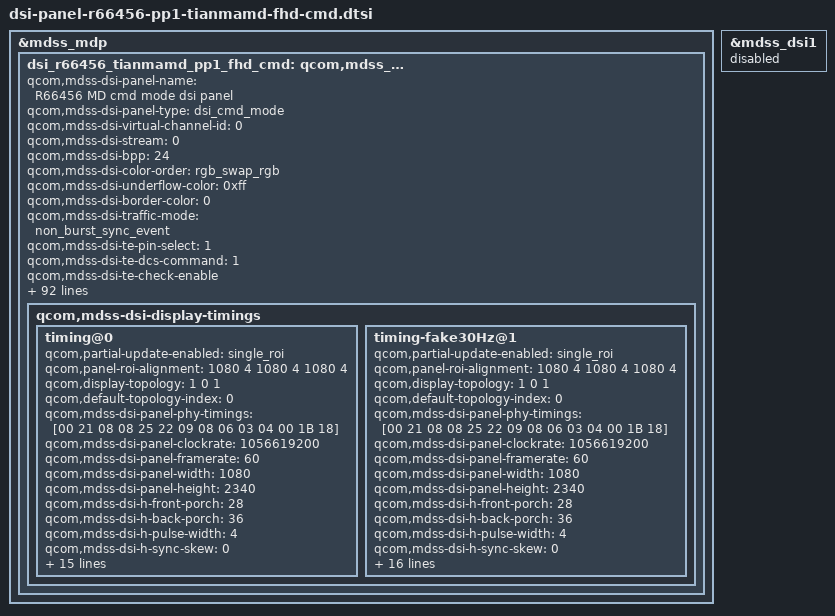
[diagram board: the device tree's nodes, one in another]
/* Copyright (c) 2014, Code Aurora Forum. All rights reserved.
 *
 * This program is free software; you can redistribute it and/or modify
 * it under the terms of the GNU General Public License version 2 and
 * only version 2 as published by the Free Software Foundation.
 *
 * This program is distributed in the hope that it will be useful,
 * but WITHOUT ANY WARRANTY; without even the implied warranty of
 * MERCHANTABILITY or FITNESS FOR A PARTICULAR PURPOSE.  See the
 * GNU General Public License for more details.
 */

&mdss_mdp {
    dsi_r66456_tianmamd_pp1_fhd_cmd: qcom,mdss_dsi_r66456_tianmamd_pp1_fhd_cmd {
		qcom,mdss-dsi-panel-name = "R66456 MD cmd mode dsi panel";
		qcom,mdss-dsi-panel-type = "dsi_cmd_mode";
		qcom,mdss-dsi-virtual-channel-id = <0>;
		qcom,mdss-dsi-stream = <0>;
		qcom,mdss-dsi-bpp = <24>;
		qcom,mdss-dsi-color-order = "rgb_swap_rgb";
		qcom,mdss-dsi-underflow-color = <0xff>;
		qcom,mdss-dsi-border-color = <0>;
		qcom,mdss-dsi-traffic-mode = "non_burst_sync_event";
		qcom,mdss-dsi-te-pin-select = <1>;
		qcom,mdss-dsi-te-dcs-command = <1>;
		qcom,mdss-dsi-te-check-enable;
		qcom,mdss-dsi-te-using-te-pin;
		qcom,mdss-dsi-lane-map = "lane_map_0123";
		qcom,mdss-dsi-bllp-eof-power-mode;
		qcom,mdss-dsi-bllp-power-mode;
		qcom,mdss-dsi-lane-0-state;
		qcom,mdss-dsi-lane-1-state;
		qcom,mdss-dsi-lane-2-state;
		qcom,mdss-dsi-lane-3-state;
		qcom,mdss-dsi-reset-sequence = <1 10>, <0 2>, <1 10>;
		qcom,mdss-dsi-dma-trigger = "trigger_sw";
		qcom,mdss-dsi-mdp-trigger = "none";
		qcom,mdss-dsi-wr-mem-start = <0x2c>;
		qcom,mdss-dsi-wr-mem-continue = <0x3c>;
		qcom,mdss-dsi-lp11-init;
		qcom,mdss-dsi-tx-eot-append;
		qcom,ulps-enabled;
		qcom,mdss-dsi-panel-hdr-enabled;
		qcom,mdss-dsi-panel-hdr-color-primaries = <14880 15935 32435 16555 14945 30910 7790 3415>;
		qcom,mdss-dsi-panel-peak-brightness = <5643000>;
		qcom,mdss-dsi-panel-blackness-level = <6134>;
		qcom,esd-check-enabled;
		qcom,mdss-dsi-panel-status-check-mode = "te_signal_check";

		lge,blmap = <
			0
			8 8 8 8 8 8 8 8 8 8 9 11 12 13 15 16 17 18 20 21
			22 24 25 26 28 29 30 32 33 34 35 37 38 39 41 42 43 45 46 47
			49 50 52 53 54 56 57 58 60 61 62 64 65 66 68 69 71 72 73 75
			76 81 86 91 96 100 105 110 115 120 125 130 135 139 144 149 154 159 164 169
			174 179 184 189 193 198 203 208 213 218 224 229 234 239 244 249 254 259 264 269
			274 279 285 290 295 300 305 310 319 328 337 346 355 364 373 382 392 401 410 419
			428 437 446 455 464 473 482 491 500 509 518 527 536 546 555 564 574 583 593 602
			611 620 630 639 649 658 668 677 686 696 705 715 724 734 743 752 762 771 781 797
			813 829 845 861 877 893 910 926 942 958 974 990 1006 1022 1038 1054 1070 1086 1102 1118
			1134 1150 1167 1183 1199 1215 1231 1247 1263 1279 1295 1311 1327 1343 1359 1375 1391 1407 1424 1440
			1456 1472 1488 1504 1520 1536 1552 1574 1597 1619 1641 1664 1686 1708 1731 1753 1775 1798 1820 1842
			1864 1887 1909 1931 1954 1976 1998 2021 2043 2065 2088 2110 2134 2159 2183 2207 2231 2256 2280 2304
			2328 2353 2377 2401 2425 2450 2474 2498 2522 2547 2571 2595 2619 2644 2668 2669 2670 2671 2672 2673
			2674 2675 2676 2677 2678 2679 2680 2681 2682 2683 2685 2686 2687 2688 2689 2690 2691 2692 2693 2694
			2695 2696 2697 2698 2699 2700 2713 2725 2738 2750 2763 2775 2788 2800 2813 2825 2838 2850 2863 2875
			2888 2900 2906 2911 2917 2922 2928 2933 2939 2944 2950 2956 2961 2967 2972 2978 2983 2989 2994 3000
			3012 3023 3035 3046 3058 3069 3081 3092 3104 3115 3127 3138 3150 3162 3173 3185 3196 3208 3219 3231
			3242 3254 3265 3277 3288 3300 3311 3321 3332 3343 3353 3364 3375 3385 3396 3407 3418 3428 3439 3450
			3460 3471 3482 3492 3503
		>;
		lge,blmap-ve = <
			0
			8 8 8 8 8 8 8 8 8 8 10 12 13 15 17 19 21 23 24 26
			28 30 32 33 35 37 39 41 42 44 46 48 50 52 53 55 57 59 61 62
			64 66 68 69 71 73 75 77 78 80 82 84 86 87 89 91 93 94 96 98
			100 106 113 119 125 132 138 145 151 157 164 170 177 183 189 196 202 209 215 221
			228 234 241 248 253 260 267 273 280 287 293 300 307 314 320 327 334 340 347 354
			360 367 374 380 387 394 400 407 419 431 443 455 466 478 490 502 514 526 538 550
			562 574 585 597 609 621 633 645 657 669 681 692 704 716 729 741 753 766 778 790
			803 815 827 839 852 864 877 889 901 914 926 938 951 963 975 988 1000 1013 1025 1047
			1068 1089 1110 1131 1152 1173 1194 1215 1236 1257 1279 1300 1321 1342 1363 1384 1405 1426 1447 1468
			1489 1510 1532 1553 1574 1595 1616 1637 1658 1679 1700 1721 1742 1764 1785 1806 1827 1848 1869 1890
			1911 1932 1953 1974 1996 2017 2038 2067 2096 2126 2155 2184 2214 2243 2272 2301 2331 2360 2389 2419
			2448 2477 2507 2536 2565 2595 2624 2653 2682 2712 2741 2770 2802 2834 2866 2898 2930 2962 2994 3026
			3058 3090 3122 3154 3186 3218 3249 3281 3313 3345 3377 3409 3441 3473 3505 3505 3505 3505 3505 3505
			3505 3505 3505 3505 3505 3505 3505 3505 3505 3505 3505 3505 3505 3505 3505 3505 3505 3505 3505 3505
			3505 3505 3505 3505 3505 3505 3505 3505 3505 3505 3505 3505 3505 3505 3505 3505 3505 3505 3505 3505
			3505 3505 3505 3505 3505 3505 3505 3505 3505 3505 3505 3505 3505 3505 3505 3505 3505 3505 3505 3505
			3505 3505 3505 3505 3505 3505 3505 3505 3505 3505 3505 3505 3505 3505 3505 3505 3505 3505 3505 3505
			3505 3505 3505 3505 3505 3505 3505 3505 3505 3505 3505 3505 3505 3505 3505 3505 3505 3505 3505 3505
			3505 3505 3505 3505 3505
		>;
		lge,blmap-ex = <
			0
			7 7 7 7 7 7 7 7 7 8 10 11 12 14 15 16 18 19 20 22
			23 24 26 27 28 30 31 32 34 35 36 38 39 40 42 43 47 52 56 60
			65 69 74 78 82 87 91 95 100 104 108 113 117 121 126 130 135 139 143 148
			152 156 161 165 169 174 178 182 187 191 196 200 204 209 213 220 227 234 240 247
			254 261 268 275 282 289 295 302 309 316 323 330 337 343 350 357 364 369 374 380
			385 390 395 400 405 411 416 421 426 431 436 442 447 452 457 462 466 471 475 480
			484 489 494 498 503 507 512 517 521 526 530 535 539 544 544 544 544 544 544 544
			552 561 569 578 586 595 603 611 620 628 637 645 653 662 670 679 687 696 704
		>;
		lge,blmap-hdr = <
			0
			8 8 8 8 8 8 8 8 8 8 10 11 13 15 16 18 20 21 23 24
			26 28 29 31 33 34 36 38 39 41 43 44 46 48 49 51 53 54 56 57
			59 61 62 64 66 67 69 71 72 74 76 77 79 81 82 84 85 87 89 90
			92 98 104 110 116 122 127 133 139 145 151 157 163 169 175 181 187 192 198 204
			210 216 223 229 234 240 246 252 258 265 271 277 283 289 295 302 308 314 320 326
			332 339 345 351 357 363 369 376 387 397 408 419 430 441 452 463 474 485 496 507
			518 529 540 551 562 573 584 595 606 617 628 639 650 661 672 684 695 706 718 729
			741 752 763 774 786 797 809 820 832 843 854 866 877 889 900 911 923 934 946 966
			985 1004 1024 1043 1063 1082 1102 1121 1141 1160 1180 1199 1219 1238 1257 1277 1296 1316 1335 1355
			1374 1394 1413 1433 1452 1471 1491 1510 1530 1549 1569 1588 1608 1627 1647 1666 1686 1705 1724 1744
			1763 1783 1802 1822 1841 1861 1880 1907 1934 1961 1988 2015 2042 2069 2096 2123 2150 2178 2205 2232
			2259 2286 2313 2340 2367 2394 2421 2448 2475 2502 2529 2556 2585 2615 2644 2674 2703 2732 2762 2791
			2821 2850 2879 2909 2938 2967 2997 3026 3056 3085 3114 3144 3173 3203 3232 3233 3233 3234 3234 3235
			3235 3236 3237 3237 3238 3238 3239 3240 3240 3241 3241 3242 3242 3243 3244 3244 3245 3245 3246 3247
			3247 3248 3248 3249 3249 3250 3255 3260 3265 3270 3275 3280 3285 3290 3296 3303 3309 3315 3321 3328
			3334 3340 3343 3346 3348 3351 3354 3357 3359 3362 3365 3368 3371 3373 3376 3379 3382 3384 3387 3390
			3393 3396 3399 3402 3405 3408 3412 3415 3418 3421 3424 3427 3430 3432 3435 3437 3439 3442 3444 3446
			3448 3451 3453 3455 3458 3460 3462 3465 3467 3469 3471 3474 3476 3478 3480 3483 3485 3487 3489 3492
			3494 3496 3498 3501 3503
		>;
		qcom,mdss-pan-physical-width-dimension = <68>;
		qcom,mdss-pan-physical-height-dimension = <147>;

		qcom,mdss-dsi-t-clk-post = <0x18>;
		qcom,mdss-dsi-t-clk-pre = <0x1B>;

		lge,use-ambient;
		lge,aod-interface-data = "semi-partial", "semi-partial", "semi-partial";
		lge,mdss-dsi-nolp-command = [
			15 01 00 00 00 00 02 B0 03
			39 01 00 00 5A 00 03 51 00 00
			15 01 00 00 32 00 02 88 00
		];
		lge,mdss-dsi-nolp-command-state = "dsi_lp_mode";

//		lge,mdss-dsi-aod-area-command = [
//			15 01 00 00 00 00 02 FE 00
//			39 01 00 00 00 00 05 30 00 00 04 37
//		];
//		lge,mdss-dsi-aod-area-command-state = "dsi_lp_mode";

		lge,mdss-dsi-lp2-command = [
			15 01 00 00 00 00 02 B0 03
			39 01 00 00 5A 00 03 51 00 00
			15 01 00 00 32 00 02 88 01
		];
		lge,mdss-dsi-lp2-command-state = "dsi_lp_mode";

		lge,use-color-manager;
		lge,color-mode-cmds-dummy = [
			15 01 00 00 00 00 02 B0 00
			39 01 00 00 00 00 43 CE C1 1C F8 FF F4 EF 0A 0A 14 EF D3 EF DC E0 2B FE EB 03 00 FB F5 F5 E5 FF B6 97 E6 B6 97 3C 00 00 00 00 00 00 00 00 00 00 00 00 00 00 00 00 00 00 00 00 00 00 00 00 00 00 00 00 00 00 00 00 00 00 00 08
			15 01 00 00 00 00 02 B0 03
		];
		lge,color-mode-cmds-dummy-state = "dsi_hs_mode";
		lge,color-mode-set = [
			39 01 00 00 00 00 43 CE C1 1C F8 FF F4 EF 0A 0A 14 EF D3 EF DC E0 2B FE EB 03 00 FB F5 F5 E5 FF B6 97 E6 B6 97 3C 00 00 00 00 00 00 00 00 00 00 00 00 00 00 00 00 00 00 00 00 00 00 00 00 00 00 00 00 00 00 00 00 00 00 00 08
			39 01 00 00 00 00 43 CE C1 1C FC EF BC 0A 0D 31 D9 0B 29 D9 EC E6 D8 F1 F1 E4 E9 EE EA FD 13 FF 00 00 FC 19 00 FF 00 FF 00 67 F8 00 FF 00 00 FF 41 26 E6 FF 00 FF FF 74 F9 EC FF FF 00 FF FB 2D F6 FF FF FF 00 FD FC 00 FF 08
			39 01 00 00 00 00 43 CE C1 1C FC EF BB 00 D9 E3 09 EB E3 DC EE E5 F2 EE E3 F7 D8 E6 09 E9 DD FF 00 00 F0 47 31 FF 00 FF 00 00 FD 37 FF 00 00 FF 3F 26 E6 FF 00 FF FF 24 FD F3 FF FF 00 FF F5 4D E1 FF FF FF 00 FD FC 46 FF 08
			39 01 00 00 00 00 43 CE C1 1C FC EF BB E2 E8 ED E1 14 E0 DC F3 E8 DC F1 E0 D9 E0 E6 DC EF D7 FF 00 00 F0 47 31 FF 00 FF 00 8F F2 4F FF 00 00 FF 3F 26 E6 FF 00 FF FF 97 F3 E8 FF FF 00 FF F0 4C F6 FF FF FF 00 FD FC 59 FF 08
			39 01 00 00 00 00 43 CE C1 1C E2 EF FF EF 0A 0A 14 EF D3 EF DC E0 2B FE EB 03 00 FB F5 F5 E5 FF B6 97 E6 B6 97 3C 00 00 00 00 00 00 00 00 00 00 00 00 00 00 00 00 00 00 00 00 00 00 00 00 00 00 00 00 00 00 00 00 00 00 00 08
			39 01 00 00 00 00 43 CE C1 1C EB F4 F4 EF 0A 0A 14 EF D3 EF DC E0 2B FE EB 03 00 FB F5 F5 E5 FF B6 97 E6 B6 97 3C 00 00 00 00 00 00 00 00 00 00 00 00 00 00 00 00 00 00 00 00 00 00 00 00 00 00 00 00 00 00 00 00 00 00 00 08
			39 01 00 00 00 00 43 CE C1 1C F8 FF F4 EF 0A 0A 14 EF D3 EF DC E0 2B FE EB 03 00 FB F5 F5 E5 FF B6 97 E6 B6 97 3C 00 00 00 00 00 00 00 00 00 00 00 00 00 00 00 00 00 00 00 00 00 00 00 00 00 00 00 00 00 00 00 00 00 00 00 08
			39 01 00 00 00 00 43 CE C0 1C F8 FF F4 EF 0A 0A 14 EF D3 EF DC E0 2B FE EB 03 00 FB F5 F5 E5 FF B6 97 E6 B6 97 3C 00 00 00 00 00 00 00 00 00 00 00 00 00 00 00 00 00 00 00 00 00 00 00 00 00 00 00 00 00 00 00 00 00 00 00 08
		];
		lge,saturation-lut = [
			39 01 00 00 00 00 2A FF 00 00 D7 28 28 FF 00 FF 00 28 D7 28 FF 00 00 FF 28 28 D7 FF 00 FF FF 28 D7 D7 FF FF 00 FF D7 28 D7 FF FF FF 00 D7 D7 28 FF
			39 01 00 00 00 00 2A FF 00 00 EB 14 14 FF 00 FF 00 14 EB 14 FF 00 00 FF 14 14 EB FF 00 FF FF 14 EB EB FF FF 00 FF EB 14 EB FF FF FF 00 EB EB 14 FF
			39 01 00 00 00 00 2A FF B6 97 E6 B6 97 3C 00 00 00 00 00 00 00 00 00 00 00 00 00 00 00 00 00 00 00 00 00 00 00 00 00 00 00 00 00 00 00 00 00 00 00
			39 01 00 00 00 00 2A FF 80 80 FF 7B 7B 5D 80 FF 80 76 FF 76 5D 80 80 FF 76 76 FF 5D 80 FF FF 76 FF FF 5D FF 80 FF FF 76 FF 5D FF FF 80 FF FF 76 5D
			39 01 00 00 00 00 2A FF 80 80 FF 76 76 5D 80 FF 80 6C FF 6C 5D 80 80 FF 6C 6C FF 5D 80 FF FF 6C FF FF 5D FF 80 FF FF 6C FF 5D FF FF 80 FF FF 6C 5D
		];
		lge,custom-rgb-hue-lut = [
			39 01 00 00 00 00 12 EF 1E 0A 14 EF F1 0F DC E0 2B EA EB 03 00 E7 E1 F5 E5
			39 01 00 00 00 00 12 EF 14 0A 14 EF E2 01 DC E0 2B F4 EB 03 00 F1 EB F5 E5
			39 01 00 00 00 00 12 EF 0A 0A 14 EF D3 EF DC E0 2B FE EB 03 00 FB F5 F5 E5
			39 01 00 00 00 00 12 EF 0A 0A 14 EF D3 EF DC E0 2B FE EB 03 00 FB F5 F5 E5
			39 01 00 00 00 00 12 EF 0A 1E 32 EF D3 EF FA E0 2B FE D7 EE 00 FB F5 E1 E5
		];
		lge,mdss-dsi-sharpness-command = [
			15 01 00 00 00 00 02 B0 00
			39 01 00 00 00 00 05 DD 33 06 07 65
			15 01 00 00 00 00 02 B0 03
		];
		lge,mdss-dsi-sharpness-command-state = "dsi_hs_mode";
		lge,sharpness-lut = [
			39 01 00 00 00 00 05 DD 33 06 07 65
			39 01 00 00 00 00 05 DD 33 06 0E 65
			39 01 00 00 00 00 05 DD 33 06 15 65
			39 01 00 00 00 00 05 DD 33 06 1C 65
			39 01 00 00 00 00 05 DD 33 06 23 65
		];
		lge,rgb-lut = [
			39 01 00 00 00 00 03 F8 FF F4
			39 01 00 00 00 00 03 F4 FB F0
			39 01 00 00 00 00 03 F0 F8 EC
			39 01 00 00 00 00 03 EC F5 E9
			39 01 00 00 00 00 03 E8 F1 E5
			39 01 00 00 00 00 03 E4 EE E2
			39 01 00 00 00 00 03 E1 EB DE
			39 01 00 00 00 00 03 DD E7 DA
			39 01 00 00 00 00 03 D9 E4 D7
			39 01 00 00 00 00 03 D5 E1 D3
			39 01 00 00 00 00 03 D1 DD D0
			39 01 00 00 00 00 03 CD DA CC
			39 01 00 00 00 00 03 CA D7 C9
			39 01 00 00 00 00 03 C6 D3 C5
			39 01 00 00 00 00 03 C2 D0 C1
			39 01 00 00 00 00 03 BE CC BE
			39 01 00 00 00 00 03 BA C9 BA
			39 01 00 00 00 00 03 B6 C6 B7
			39 01 00 00 00 00 03 B2 C2 B3
			39 01 00 00 00 00 03 AF BF AF
			39 01 00 00 00 00 03 AB BC AC
			39 01 00 00 00 00 03 A7 B8 A8
			39 01 00 00 00 00 03 A3 B5 A5
			39 01 00 00 00 00 03 9F B2 A1
		];

		/* ACO */
		lge,use-ace-ctrl;
		lge,default-ace-mode = <1>;
		lge,mdss-dsi-ace-tune-command = [
			15 01 00 00 00 00 02 B0 00
			39 01 00 00 00 00 0C BC 33 25 CD 2B 19 06 03 C0 00 00 00
			15 01 00 00 00 00 02 B0 03
			15 01 00 00 14 00 02 55 00
			15 01 00 00 14 00 02 53 00
		];
		lge,mdss-dsi-ace-cmmand-state = "dsi_hs_mode";
		lge,ace-lut = [
			39 01 00 00 00 00 0C BC 33 25 FF 2B 19 22 53 C0 00 00 00
			39 01 00 00 00 00 0C BC 3B 45 CD 2B 19 59 03 C0 00 00 00
		];

		/* IRC */
		lge,use-irc-ctrl;
		lge,mdss-dsi-irc-command = [
			15 01 00 00 00 00 02 B0 80
			15 01 00 00 00 00 02 D3 01
			15 01 00 00 00 00 02 B0 03
		];
		lge,mdss-dsi-irc-command-state = "dsi_hs_mode";

		/* FP LHBM */
		lge,use-fp-lhbm;
		lge,mdss-dsi-fp-lhbm-command = [
			15 01 00 00 00 00 02 B0 80
			15 01 00 00 14 00 02 CC 11
			15 01 00 00 00 00 02 B0 03
		];
		lge,mdss-dsi-fp-lhbm-command-state = "dsi_hs_mode";

		lge,mdss-dsi-fp-lhbm-aod-command = [
			15 01 00 00 00 00 02 B0 80
			39 01 00 00 14 00 1F B6 42 34 01 05 00 00 09 23 07 30 09 23 02 1C 01 F4 00 00 00 00 01 0E 01 0E 00 00 02 3B 58 0C
			15 01 00 00 00 00 02 B0 03
		];
		lge,mdss-dsi-fp-lhbm-aod-command-state = "dsi_hs_mode";

		lge,mdss-dsi-fp-lhbm-br-lvl-command = [
			15 01 00 00 00 00 02 B0 80
			39 01 00 00 00 00 04 E2 63 00 FF
			15 01 00 00 00 00 02 B0 03
		];
		lge,mdss-dsi-fp-lhbm-br-lvl-command-state = "dsi_hs_mode";

		/* tc Perf */
		lge,use-tc-perf;
		lge,mdss-dsi-tc-perf-command = [
			15 01 00 00 00 00 02 B0 00
			39 01 00 00 00 00 F2 CF 0F 00 00 00 00 00 00 00 0C 00 53 01 3B 02 11 0A 56 0E C4 04 04 04 04 04 04 04 04 04 05 05 06 06 07 07 07 07 08 08 09 00 FF 00 FF 00 FF 00 FF 00 FF 00 FF 00 B8 00 B8 00 B8 00 B8 00 B8 00 B8 00 B8 00 B8 00 B7 03 99 03 99 03 99 03 99 03 99 03 FF 03 FF 03 FF 03 FF 03 FF 03 FF 00 B8 00 B8 00 B8 00 B8 00 B8 00 B8 00 B8 00 B8 00 B8 03 99 03 99 03 99 03 99 03 99 01 2F 01 2F 01 2F 01 2F 01 2F 01 2F 01 2F 01 2F 01 2F 01 2F 01 2F 01 2F 01 2F 01 2F 01 2F 01 2F 01 2F 01 2F 01 2F 01 2F 26 26 26 26 26 26 26 26 26 26 26 26 26 26 26 26 26 26 26 26 00 00 0F FF 0F FF 0F FF 0F FF 0F FF 00 00 00 41 00 41 01 BC 01 BC 06 A8 06 A8 0F 85 0F 85 0F 85 0F 85 0F 85 0F 85 0F 85 2B 2B 2B 2B 2B 2B 2B 2B 2B 2B 2B 2B 2B 2B 2B 2B 2B 2B 2B 2B 19 19
			15 01 00 00 00 00 02 B0 03
		];
		lge,mdss-dsi-tc-perf-command-state = "dsi_hs_mode";

		qcom,mdss-dsi-display-timings {
			timing@0{
				qcom,partial-update-enabled = "single_roi";
				qcom,panel-roi-alignment = <1080 4 1080 4 1080 4>;
				qcom,display-topology = <1 0 1>;
				qcom,default-topology-index = <0>;
				qcom,mdss-dsi-panel-phy-timings = [00 21 08 08 25 22 09 08 06 03 04 00 1B 18];
				qcom,mdss-dsi-panel-clockrate = <1056619200>;
				qcom,mdss-dsi-panel-framerate = <60>;
				qcom,mdss-dsi-panel-width = <1080>;
				qcom,mdss-dsi-panel-height = <2340>;
				qcom,mdss-dsi-h-front-porch = <28>;
				qcom,mdss-dsi-h-back-porch = <36>;
				qcom,mdss-dsi-h-pulse-width = <4>;
				qcom,mdss-dsi-h-sync-skew = <0>;
				qcom,mdss-dsi-v-back-porch = <4>;
				qcom,mdss-dsi-v-front-porch = <12>;
				qcom,mdss-dsi-v-pulse-width = <4>;
				qcom,mdss-dsi-h-left-border = <0>;
				qcom,mdss-dsi-h-right-border = <0>;
				qcom,mdss-dsi-v-top-border = <0>;
				qcom,mdss-dsi-v-bottom-border = <0>;
				qcom,mdss-mdp-transfer-time-us = <15200>;

				qcom,mdss-dsi-on-command = [
					15 01 00 00 00 00 02 B0 00
					39 01 00 00 00 00 3A BB 59 FF FF FF EF CF AB 87 63 3F C0 C0 C0 C0 42 40 3E 3C 3A 64 00 FF FF FF FF FF FF FF FF FF 00 00 00 00 00 00 00 00 00 00 00 42 00 00 5A 00 5A 20 0E C3 0F FF 0F FF 0F FF 14
					39 01 00 00 00 00 86 C1 D0 42 04 38 00 3F 05 48 00 15 55 10 08 10 04 99 89 00 02 10 00 10 00 00 33 33 30 00 33 FF 00 00 00 00 20 00 20 00 C8 40 51 51 00 00 00 00 10 00 00 10 01 10 02 90 00 00 10 00 00 00 00 10 00 00 20 04 20 02 01 80 00 00 00 00 20 02 10 01 10 80 00 00 00 00 00 00 10 00 00 00 00 00 00 00 00 00 10 00 00 00 00 00 00 00 00 00 00 00 00 00 00 00 00 06 08 06 08 00 00 00 00 00 00 00 00 00 00 00 00 00 00 00 00
					39 01 00 00 00 00 1A C2 09 24 08 00 00 04 00 00 00 00 00 00 09 30 00 00 00 00 00 00 01 00 30 00 6C
					39 01 00 00 00 00 2F C3 00 26 17 02 88 88 A8 A8 A8 A8 A8 A8 A8 A8 AA 09 00 00 10 00 00 00 00 00 80 00 00 00 10 09 C4 03 E8 03 E8 03 E8 00 0A 00 0A 00 0A 01 03 03
					39 01 00 00 00 00 3D C4 80 00 AA 00 00 00 00 00 00 00 00 01 00 00 00 1F 00 1F 00 00 00 00 00 00 00 00 0F 00 00 00 00 00 22 00 00 00 11 11 00 11 00 00 98 31 03 00 00 00 00 00 00 00 00 00 00 00 00 00 00 00
					39 01 00 00 00 00 43 CE C1 1C E7 FC EE 07 1A 1A 14 15 D3 EF DC 2C 2B FE EB 03 00 FB F8 FA E5 FF B6 97 F0 B6 97 3C 00 00 00 00 00 00 00 00 00 00 00 00 00 00 00 00 00 00 00 00 00 00 00 00 00 00 00 00 00 00 00 00 00 00 00 08
					39 01 00 00 00 00 0A D1 09 30 02 1C 26 1D 4E 1E 00
					15 01 00 00 00 00 02 B0 80
					39 01 00 00 00 00 87 E2 63 00 FF 00 FF 00 FF FF FF 00 FF 00 00 00 FF 00 00 00 FF FF FF FF 02 1C 08 3A 02 00 02 1C A7 DA 01 F4 07 DA 01 D8 07 F6 01 D8 A7 F6 01 BC 08 12 01 BC 08 3A 01 BC A8 3A 01 BC 08 62 01 D8 08 7E 01 D8 A8 7E 01 F4 08 9A 02 1C 08 9A 12 1C F7 DA 02 44 07 DA 02 60 07 F6 12 60 F7 F6 02 7C 08 12 02 7C 08 3A 12 7C F8 3A 02 7C 08 62 02 60 08 7E 12 60 F8 7E 02 44 08 9A 02 1C 08 9A 03 02 1C 08 3A 00 00 00 00 00
					39 01 00 00 00 00 0B E1 01 00 21 1A 0F FF 04 04 42 02
					39 01 00 00 00 00 1F B6 42 34 01 05 00 00 09 23 07 30 09 23 02 1C 01 F4 00 00 00 00 01 0E 01 0E 00 00 02 3B 58 0C
					39 01 00 00 00 00 5C DF 57 50 00 00 00 00 00 10 2E 32 28 A0 AA AA A0 AA AA A0 00 00 00 00 03 84 00 09 00 6A 35 3E 00 00 51 50 00 00 60 07 60 07 00 60 01 00 00 00 00 00 00 00 00 00 00 00 04 30 00 00 00 00 00 00 00 00 4C 00 01 00 00 00 00 00 00 00 00 00 00 00 00 00 00 00 00 00 AA AA 0A AA AA 0A 0B
					15 01 00 00 00 00 02 E6 00
					15 01 00 00 00 00 02 B0 03
					15 01 00 00 00 00 02 35 00
					39 01 00 00 00 00 05 2A 00 00 04 37
					39 01 00 00 00 00 05 2B 00 00 09 23
					05 01 00 00 00 00 01 29
					05 01 00 00 96 00 01 11
				];
				qcom,mdss-dsi-on-command-state = "dsi_lp_mode";

				qcom,mdss-dsi-off-command = [
					15 01 00 00 00 00 02 B0 03
					39 01 00 00 5A 00 03 51 00 00
					05 01 00 00 00 00 01 28
					05 01 00 00 96 00 01 10
				];
				qcom,mdss-dsi-off-command-state = "dsi_lp_mode";
				qcom,mdss-dsi-h-sync-pulse = <0>;
			};
			timing-fake30Hz@1{
				qcom,partial-update-enabled = "single_roi";
				qcom,panel-roi-alignment = <1080 4 1080 4 1080 4>;
				qcom,display-topology = <1 0 1>;
				qcom,default-topology-index = <0>;
				qcom,mdss-dsi-panel-phy-timings = [00 21 08 08 25 22 09 08 06 03 04 00 1B 18];
				qcom,mdss-dsi-panel-clockrate = <1056619200>;
				qcom,mdss-dsi-panel-framerate = <60>;
				qcom,mdss-dsi-panel-width = <1080>;
				qcom,mdss-dsi-panel-height = <2340>;
				qcom,mdss-dsi-h-front-porch = <28>;
				qcom,mdss-dsi-h-back-porch = <36>;
				qcom,mdss-dsi-h-pulse-width = <4>;
				qcom,mdss-dsi-h-sync-skew = <0>;
				qcom,mdss-dsi-v-back-porch = <4>;
				qcom,mdss-dsi-v-front-porch = <12>;
				qcom,mdss-dsi-v-pulse-width = <4>;
				qcom,mdss-dsi-h-left-border = <0>;
				qcom,mdss-dsi-h-right-border = <0>;
				qcom,mdss-dsi-v-top-border = <0>;
				qcom,mdss-dsi-v-bottom-border = <0>;
				qcom,mdss-mdp-tiransfer-time-us = <15200>;
				lge,mdss-dsi-panel-framerate-div = <2>;

				qcom,mdss-dsi-on-command = [
					15 01 00 00 00 00 02 B0 00
					39 01 00 00 00 00 3A BB 59 FF FF FF EF CF AB 87 63 3F C0 C0 C0 C0 42 40 3E 3C 3A 64 00 FF FF FF FF FF FF FF FF FF 00 00 00 00 00 00 00 00 00 00 00 42 00 00 5A 00 5A 20 0E C3 0F FF 0F FF 0F FF 14
					39 01 00 00 00 00 86 C1 D0 42 04 38 00 3F 05 48 00 15 55 10 08 10 04 99 89 00 02 10 00 10 00 00 33 33 30 00 33 FF 00 00 00 00 20 00 20 00 C8 40 51 51 00 00 00 00 10 00 00 10 01 10 02 90 00 00 10 00 00 00 00 10 00 00 20 04 20 02 01 80 00 00 00 00 20 02 10 01 10 80 00 00 00 00 00 00 10 00 00 00 00 00 00 00 00 00 10 00 00 00 00 00 00 00 00 00 00 00 00 00 00 00 00 06 08 06 08 00 00 00 00 00 00 00 00 00 00 00 00 00 00 00 00
					39 01 00 00 00 00 1A C2 09 24 08 00 00 04 00 00 00 00 00 00 09 30 00 00 00 00 00 00 01 00 30 00 6C
					39 01 00 00 00 00 2F C3 00 26 17 02 88 88 A8 A8 A8 A8 A8 A8 A8 A8 AA 09 00 00 10 00 00 00 00 00 80 00 00 00 10 09 C4 03 E8 03 E8 03 E8 00 0A 00 0A 00 0A 01 03 03
					39 01 00 00 00 00 3D C4 80 00 AA 00 00 00 00 00 00 00 00 01 00 00 00 1F 00 1F 00 00 00 00 00 00 00 00 0F 00 00 00 00 00 22 00 00 00 11 11 00 11 00 00 98 31 03 00 00 00 00 00 00 00 00 00 00 00 00 00 00 00
					39 01 00 00 00 00 43 CE C1 1C E7 FC EE 07 1A 1A 14 15 D3 EF DC 2C 2B FE EB 03 00 FB F8 FA E5 FF B6 97 F0 B6 97 3C 00 00 00 00 00 00 00 00 00 00 00 00 00 00 00 00 00 00 00 00 00 00 00 00 00 00 00 00 00 00 00 00 00 00 00 08
					39 01 00 00 00 00 0A D1 09 30 02 1C 26 1D 4E 1E 00
					15 01 00 00 00 00 02 B0 80
					39 01 00 00 00 00 87 E2 63 00 FF 00 FF 00 FF FF FF 00 FF 00 00 00 FF 00 00 00 FF FF FF FF 02 1C 08 3A 02 00 02 1C A7 DA 01 F4 07 DA 01 D8 07 F6 01 D8 A7 F6 01 BC 08 12 01 BC 08 3A 01 BC A8 3A 01 BC 08 62 01 D8 08 7E 01 D8 A8 7E 01 F4 08 9A 02 1C 08 9A 12 1C F7 DA 02 44 07 DA 02 60 07 F6 12 60 F7 F6 02 7C 08 12 02 7C 08 3A 12 7C F8 3A 02 7C 08 62 02 60 08 7E 12 60 F8 7E 02 44 08 9A 02 1C 08 9A 03 02 1C 08 3A 00 00 00 00 00
					39 01 00 00 00 00 0B E1 01 00 21 1A 0F FF 04 04 42 02
					39 01 00 00 00 00 1F B6 42 34 01 05 00 00 09 23 07 30 09 23 02 1C 01 F4 00 00 00 00 01 0E 01 0E 00 00 02 3B 58 0C
					39 01 00 00 00 00 5C DF 57 50 00 00 00 00 00 10 2E 32 28 A0 AA AA A0 AA AA A0 00 00 00 00 03 84 00 09 00 6A 35 3E 00 00 51 50 00 00 60 07 60 07 00 60 01 00 00 00 00 00 00 00 00 00 00 00 04 30 00 00 00 00 00 00 00 00 4C 00 01 00 00 00 00 00 00 00 00 00 00 00 00 00 00 00 00 00 AA AA 0A AA AA 0A 0B
					15 01 00 00 00 00 02 E6 00
					15 01 00 00 00 00 02 B0 03
					15 01 00 00 00 00 02 35 00
					39 01 00 00 00 00 05 2A 00 00 04 37
					39 01 00 00 00 00 05 2B 00 00 09 23
					05 01 00 00 00 00 01 29
					05 01 00 00 96 00 01 11
				];
				qcom,mdss-dsi-on-command-state = "dsi_lp_mode";

				qcom,mdss-dsi-off-command = [
					15 01 00 00 00 00 02 B0 03
					39 01 00 00 5A 00 03 51 00 00
					05 01 00 00 00 00 01 28
					05 01 00 00 96 00 01 10
				];
				qcom,mdss-dsi-off-command-state = "dsi_lp_mode";
				qcom,mdss-dsi-h-sync-pulse = <0>;
			};
		};
	};
};
/*
&spmi_bus {
	qcom,pmi8998@3 {
		labibb: qpnp-labibb-regulator {
			status = "disabled";
		};
	};
};
*/
&mdss_dsi1 {
	status = "disabled";
};
